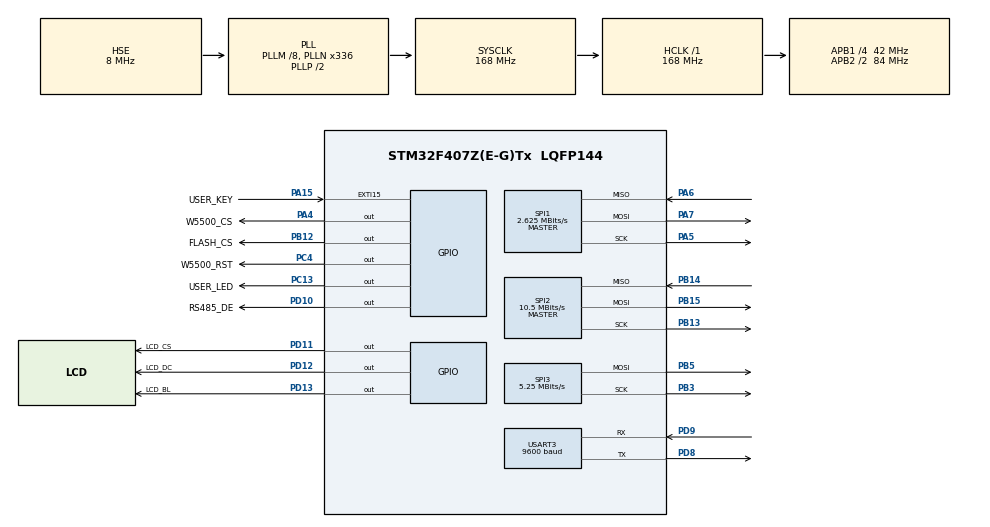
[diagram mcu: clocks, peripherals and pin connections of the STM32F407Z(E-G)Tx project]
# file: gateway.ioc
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Dma.Request0=USART3_RX
Dma.Request1=SPI3_TX
Dma.SPI3_TX.1.Direction=DMA_MEMORY_TO_PERIPH
Dma.SPI3_TX.1.FIFOMode=DMA_FIFOMODE_DISABLE
Dma.SPI3_TX.1.Instance=DMA1_Stream5
Dma.SPI3_TX.1.MemDataAlignment=DMA_MDATAALIGN_BYTE
Dma.SPI3_TX.1.MemInc=DMA_MINC_ENABLE
Dma.SPI3_TX.1.Mode=DMA_NORMAL
Dma.SPI3_TX.1.PeriphDataAlignment=DMA_PDATAALIGN_BYTE
Dma.SPI3_TX.1.PeriphInc=DMA_PINC_DISABLE
Dma.SPI3_TX.1.Priority=DMA_PRIORITY_LOW
Dma.USART3_RX.0.Direction=DMA_PERIPH_TO_MEMORY
Dma.USART3_RX.0.FIFOMode=DMA_FIFOMODE_DISABLE
Dma.USART3_RX.0.Instance=DMA1_Stream1
Dma.USART3_RX.0.MemDataAlignment=DMA_MDATAALIGN_BYTE
Dma.USART3_RX.0.MemInc=DMA_MINC_ENABLE
Dma.USART3_RX.0.Mode=DMA_CIRCULAR
Dma.USART3_RX.0.PeriphDataAlignment=DMA_PDATAALIGN_BYTE
Dma.USART3_RX.0.PeriphInc=DMA_PINC_DISABLE
Dma.USART3_RX.0.Priority=DMA_PRIORITY_HIGH
FREERTOS.Tasks01=defaultTask,32,128,StartDefaultTask,Default,NULL,Dynamic,NULL,NULL
FREERTOS.configCHECK_FOR_STACK_OVERFLOW=2
FREERTOS.configTOTAL_HEAP_SIZE=32768
FREERTOS.configUSE_MALLOC_FAILED_HOOK=1
IWDG.Prescaler=IWDG_PRESCALER_256
IWDG.Reload=499
Mcu.Family=STM32F4
Mcu.Name=STM32F407Z(E-G)Tx
Mcu.Package=LQFP144
NVIC.DMA1_Stream1_IRQn=true\:6\:0\:true\:false\:true\:true\:false\:true\:true
NVIC.DMA1_Stream5_IRQn=true\:6\:0\:true\:false\:true\:true\:false\:true\:true
NVIC.EXTI15_10_IRQn=true\:6\:0\:true\:false\:true\:true\:true\:true\:true
NVIC.PriorityGroup=NVIC_PRIORITYGROUP_4
NVIC.TIM6_DAC_IRQn=true\:15\:0\:false\:false\:true\:false\:false\:true\:true
NVIC.TimeBase=TIM6_DAC_IRQn
NVIC.TimeBaseIP=TIM6
NVIC.USART3_IRQn=true\:6\:0\:true\:false\:true\:true\:true\:true\:true
PA13.Mode=Serial_Wire
PA13.Signal=SYS_JTMS-SWDIO
PA14.Mode=Serial_Wire
PA14.Signal=SYS_JTCK-SWCLK
PA15.GPIO_Label=USER_KEY
PA15.GPIO_ModeDefaultEXTI=GPIO_MODE_IT_FALLING
PA15.GPIO_PuPd=GPIO_PULLUP
PA15.Signal=GPXTI15
PA4.GPIO_Label=W5500_CS
PA4.GPIO_Speed=GPIO_SPEED_FREQ_HIGH
PA4.PinState=GPIO_PIN_SET
PA4.Signal=GPIO_Output
PA5.Mode=Full_Duplex_Master
PA5.Signal=SPI1_SCK
PA6.Mode=Full_Duplex_Master
PA6.Signal=SPI1_MISO
PA7.Mode=Full_Duplex_Master
PA7.Signal=SPI1_MOSI
PB12.GPIO_Label=FLASH_CS
PB12.GPIO_Speed=GPIO_SPEED_FREQ_HIGH
PB12.PinState=GPIO_PIN_SET
PB12.Signal=GPIO_Output
PB13.Mode=Full_Duplex_Master
PB13.Signal=SPI2_SCK
PB14.Mode=Full_Duplex_Master
PB14.Signal=SPI2_MISO
PB15.Mode=Full_Duplex_Master
PB15.Signal=SPI2_MOSI
PB3.Mode=TX_Only_Simplex_Unidirect_Master
PB3.Signal=SPI3_SCK
PB5.Mode=TX_Only_Simplex_Unidirect_Master
PB5.Signal=SPI3_MOSI
PC13-ANTI_TAMP.GPIO_Label=USER_LED
PC13-ANTI_TAMP.PinState=GPIO_PIN_SET
PC13-ANTI_TAMP.Signal=GPIO_Output
PC4.GPIO_Label=W5500_RST
PC4.GPIO_Speed=GPIO_SPEED_FREQ_HIGH
PC4.PinState=GPIO_PIN_SET
PC4.Signal=GPIO_Output
PD10.GPIO_Label=RS485_DE
PD10.Signal=GPIO_Output
PD11.GPIO_Label=LCD_CS
PD11.GPIO_Speed=GPIO_SPEED_FREQ_HIGH
PD11.PinState=GPIO_PIN_SET
PD11.Signal=GPIO_Output
PD12.GPIO_Label=LCD_DC
PD12.GPIO_Speed=GPIO_SPEED_FREQ_HIGH
PD12.Signal=GPIO_Output
PD13.GPIO_Label=LCD_BL
PD13.PinState=GPIO_PIN_SET
PD13.Signal=GPIO_Output
PD8.Mode=Asynchronous
PD8.Signal=USART3_TX
PD9.GPIO_PuPd=GPIO_PULLUP
PD9.Mode=Asynchronous
PD9.Signal=USART3_RX
PH0-OSC_IN.Mode=HSE-External-Oscillator
PH0-OSC_IN.Signal=RCC_OSC_IN
PH1-OSC_OUT.Mode=HSE-External-Oscillator
PH1-OSC_OUT.Signal=RCC_OSC_OUT
ProjectManager.HeapSize=0x200
ProjectManager.StackSize=0x400
ProjectManager.TargetToolchain=CMake
RCC.48MHZClocksFreq_Value=48000000
RCC.AHBFreq_Value=168000000
RCC.APB1CLKDivider=RCC_HCLK_DIV4
RCC.APB1Freq_Value=42000000
RCC.APB1TimFreq_Value=84000000
RCC.APB2CLKDivider=RCC_HCLK_DIV2
RCC.APB2Freq_Value=84000000
RCC.APB2TimFreq_Value=168000000
RCC.CortexFreq_Value=168000000
RCC.HCLKFreq_Value=168000000
RCC.HSE_VALUE=8000000
RCC.HSI_VALUE=16000000
RCC.LSE_VALUE=32768
RCC.PLLM=8
RCC.PLLN=336
RCC.PLLQ=7
RCC.PLLSourceVirtual=RCC_PLLSOURCE_HSE
RCC.SYSCLKFreq_VALUE=168000000
RCC.SYSCLKSource=RCC_SYSCLKSOURCE_PLLCLK
RCC.VCOOutputFreq_Value=336000000
SPI1.BaudRatePrescaler=SPI_BAUDRATEPRESCALER_32
SPI1.CalculateBaudRate=2.625 MBits/s
SPI1.Direction=SPI_DIRECTION_2LINES
SPI1.Mode=SPI_MODE_MASTER
SPI1.VirtualType=VM_MASTER
SPI2.BaudRatePrescaler=SPI_BAUDRATEPRESCALER_4
SPI2.CalculateBaudRate=10.5 MBits/s
SPI2.Direction=SPI_DIRECTION_2LINES
SPI2.Mode=SPI_MODE_MASTER
SPI2.VirtualType=VM_MASTER
SPI3.BaudRatePrescaler=SPI_BAUDRATEPRESCALER_8
SPI3.CalculateBaudRate=5.25 MBits/s
SPI3.Direction=SPI_DIRECTION_2LINES
SPI3.Mode=SPI_MODE_MASTER
SPI3.VirtualType=VM_MASTER
TIM2.Prescaler=83
USART3.BaudRate=9600
USART3.VirtualMode=VM_ASYNC
VP_FREERTOS_VS_CMSIS_V2.Mode=CMSIS_V2
VP_IWDG_VS_IWDG.Mode=IWDG_Activate
VP_SYS_VS_tim6.Mode=TIM6
VP_TIM2_VS_ClockSourceINT.Mode=Internal
board=custom

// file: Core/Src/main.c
/* USER CODE BEGIN Header */

/**
  ******************************************************************************
  * @file           : main.c
  * @brief          : Main program body
  ******************************************************************************
  * @attention
  *
  * Copyright (c) 2026 STMicroelectronics.
  * All rights reserved.
  *
  * This software is licensed under terms that can be found in the LICENSE file
  * in the root directory of this software component.
  * If no LICENSE file comes with this software, it is provided AS-IS.
  *
  ******************************************************************************
  */
  /* USER CODE END Header */
#include "main.h"
#include "cmsis_os.h"
#include "dma.h"
#include "iwdg.h"
#include "spi.h"
#include "tim.h"
#include "usart.h"
#include "gpio.h"

/* USER CODE BEGIN Includes */

#include "gateway.h"
  /* USER CODE END Includes */

void SystemClock_Config(void);
void MX_FREERTOS_Init(void);

int main(void)
{

  /* USER CODE BEGIN 1 */
  AppWatchdog_CaptureReset();
  /* USER CODE END 1 */

  /* MCU Configuration--------------------------------------------------------*/

  /* Reset of all peripherals, Initializes the Flash interface and the Systick. */
  HAL_Init();

  /* Configure the system clock */
  SystemClock_Config();

  /* Initialize all configured peripherals */
  MX_GPIO_Init();
  MX_DMA_Init();
  MX_USART3_UART_Init();
  MX_TIM2_Init();
  MX_SPI3_Init();

  MX_SPI1_Init();

  /* USER CODE BEGIN 2 */
  MX_SPI2_Init();
  Gateway_Init();
  /* USER CODE END 2 */

  /* Init scheduler */
  osKernelInitialize();

  /* Call init function for freertos objects (in cmsis_os2.c) */
  MX_FREERTOS_Init();

  /* Start scheduler */
  osKernelStart();

  /* We should never get here as control is now taken by the scheduler */

  /* Infinite loop */
  while (1)
  {

  }
}

void SystemClock_Config(void)
{
  RCC_OscInitTypeDef RCC_OscInitStruct = {0};
  RCC_ClkInitTypeDef RCC_ClkInitStruct = {0};

  /** Configure the main internal regulator output voltage
  */
  __HAL_RCC_PWR_CLK_ENABLE();
  __HAL_PWR_VOLTAGESCALING_CONFIG(PWR_REGULATOR_VOLTAGE_SCALE1);

  /** Initializes the RCC Oscillators according to the specified parameters
  * in the RCC_OscInitTypeDef structure.
  */
  RCC_OscInitStruct.OscillatorType = RCC_OSCILLATORTYPE_LSI|RCC_OSCILLATORTYPE_HSE;
  RCC_OscInitStruct.HSEState = RCC_HSE_ON;
  RCC_OscInitStruct.LSIState = RCC_LSI_ON;
  RCC_OscInitStruct.PLL.PLLState = RCC_PLL_ON;
  RCC_OscInitStruct.PLL.PLLSource = RCC_PLLSOURCE_HSE;
  RCC_OscInitStruct.PLL.PLLM = 8;
  RCC_OscInitStruct.PLL.PLLN = 336;
  RCC_OscInitStruct.PLL.PLLP = RCC_PLLP_DIV2;
  RCC_OscInitStruct.PLL.PLLQ = 7;
  if (HAL_RCC_OscConfig(&RCC_OscInitStruct) != HAL_OK)
  {
    Error_Handler();
  }

  /** Initializes the CPU, AHB and APB buses clocks
  */
  RCC_ClkInitStruct.ClockType = RCC_CLOCKTYPE_HCLK|RCC_CLOCKTYPE_SYSCLK
                              |RCC_CLOCKTYPE_PCLK1|RCC_CLOCKTYPE_PCLK2;
  RCC_ClkInitStruct.SYSCLKSource = RCC_SYSCLKSOURCE_PLLCLK;
  RCC_ClkInitStruct.AHBCLKDivider = RCC_SYSCLK_DIV1;
  RCC_ClkInitStruct.APB1CLKDivider = RCC_HCLK_DIV4;
  RCC_ClkInitStruct.APB2CLKDivider = RCC_HCLK_DIV2;

  if (HAL_RCC_ClockConfig(&RCC_ClkInitStruct, FLASH_LATENCY_5) != HAL_OK)
  {
    Error_Handler();
  }
}

void HAL_TIM_PeriodElapsedCallback(TIM_HandleTypeDef *htim)
{
  if (htim->Instance == TIM6) {
    HAL_IncTick();
  }
}

void Error_Handler(void)
{
  __disable_irq();
  while (1)
  {
  }
}

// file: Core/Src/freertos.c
/* USER CODE BEGIN Header */

/**
  ******************************************************************************
  * File Name          : freertos.c
  * Description        : Code for freertos applications
  ******************************************************************************
  * @attention
  *
  * Copyright (c) 2026 STMicroelectronics.
  * All rights reserved.
  *
  * This software is licensed under terms that can be found in the LICENSE file
  * in the root directory of this software component.
  * If no LICENSE file comes with this software, it is provided AS-IS.
  *
  ******************************************************************************
  */
  /* USER CODE END Header */

#include "FreeRTOS.h"
#include "task.h"
#include "main.h"
#include "cmsis_os.h"

/* USER CODE BEGIN Includes */
#include "gateway.h"
  /* USER CODE END Includes */

/* Definitions for defaultTask */
osThreadId_t defaultTaskHandle;
const osThreadAttr_t defaultTask_attributes = {
  .name = "defaultTask",
  .stack_size = 128 * 4,
  .priority = (osPriority_t) osPriorityAboveNormal,
};

void StartDefaultTask(void *argument);

void MX_FREERTOS_Init(void); /* (MISRA C 2004 rule 8.1) */

/* Hook prototypes */
void vApplicationStackOverflowHook(xTaskHandle xTask, signed char *pcTaskName);
void vApplicationMallocFailedHook(void);

/* USER CODE BEGIN 4 */
void vApplicationStackOverflowHook(xTaskHandle task, signed char *name)
{
    (void)task; (void)name;
    Error_Handler();
}
  /* USER CODE END 4 */

/* USER CODE BEGIN 5 */
void vApplicationMallocFailedHook(void)
{
    Error_Handler();
}
  /* USER CODE END 5 */

void MX_FREERTOS_Init(void) {

  /* Create the thread(s) */
  /* creation of defaultTask */
  defaultTaskHandle = osThreadNew(StartDefaultTask, NULL, &defaultTask_attributes);

  /* USER CODE BEGIN RTOS_THREADS */
Gateway_StartTasks();
  /* USER CODE END RTOS_THREADS */

}

void StartDefaultTask(void *argument)
{
  /* USER CODE BEGIN StartDefaultTask */
  (void)argument;
  osThreadExit(); /* CubeMX占位任务退出，业务任务单独运行。 */
  /* USER CODE END StartDefaultTask */
}
